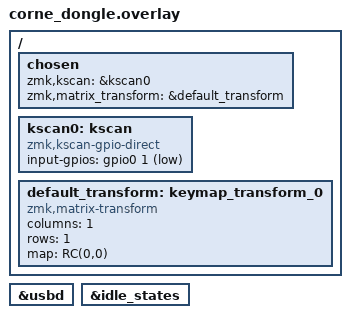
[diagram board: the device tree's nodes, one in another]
#include <dt-bindings/zmk/matrix_transform.h>

/ {
    chosen {
        zmk,kscan = &kscan0;
        zmk,matrix_transform = &default_transform;
    };

    kscan0: kscan {
        compatible = "zmk,kscan-gpio-direct";
        input-gpios = <&gpio0 1 (GPIO_ACTIVE_LOW | GPIO_PULL_UP)>;
    };

    default_transform: keymap_transform_0 {
        compatible = "zmk,matrix-transform";
        columns = <1>;
        rows = <1>;
        map = <RC(0,0)>;
    };
};

&usbd {
    status = "okay";
};

&idle_states {
    status = "okay";
};
